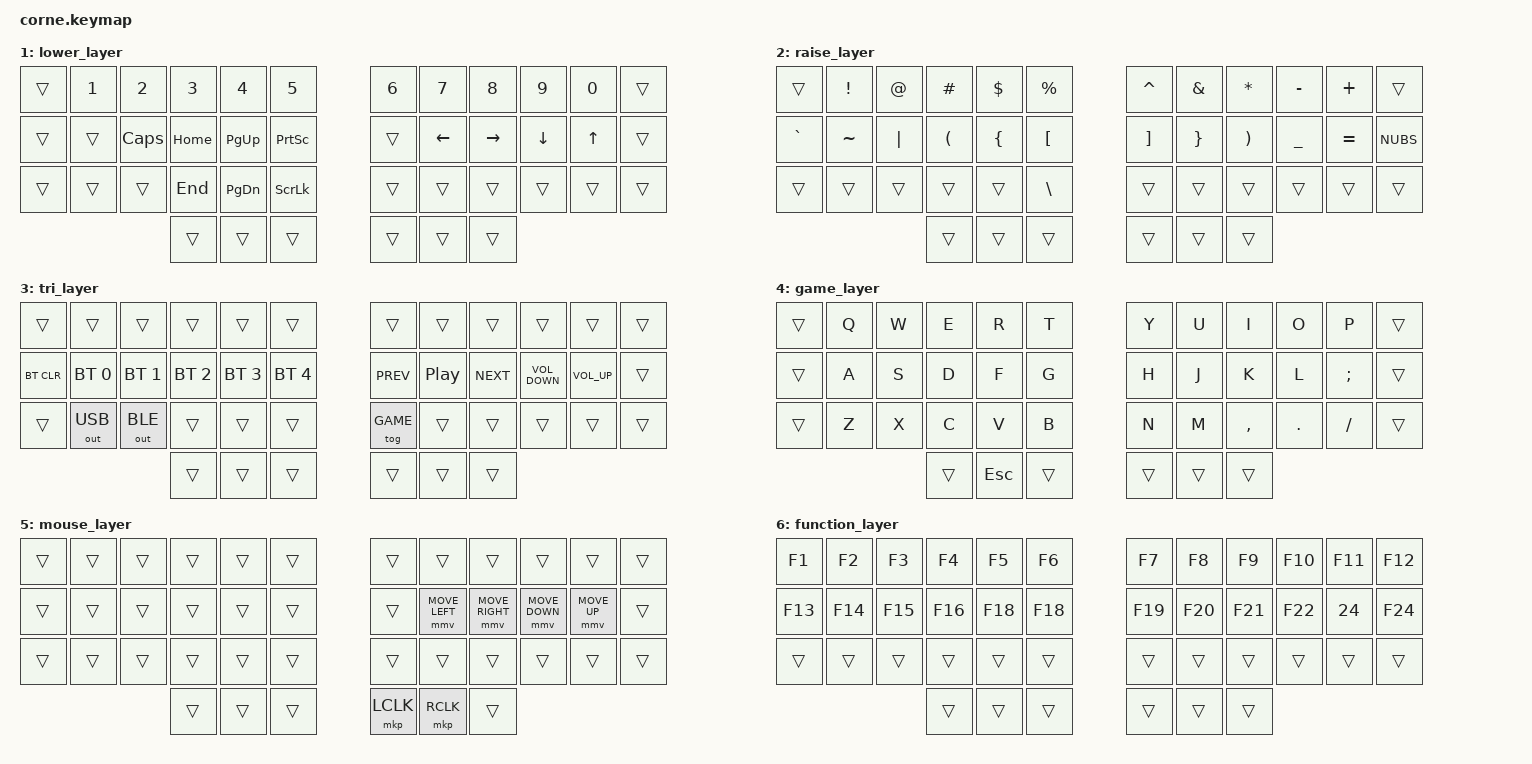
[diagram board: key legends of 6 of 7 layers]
#include <behaviors.dtsi>
#include <dt-bindings/zmk/keys.h>
#include <dt-bindings/zmk/outputs.h>
#include <dt-bindings/zmk/bt.h>
#include <dt-bindings/zmk/mouse.h>

// Home row mods macro
#define HRML(k2,k3,k4,k5) &ht LSHFT k2 &ht LALT  k3  &ht LCTRL k4  &ht LGUI  k5
#define HRMR(k1,k2,k3,k4) &ht LALT  k1 &ht RCTRL k2  &ht RGUI  k3  &ht RSHFT k4

#define ZMK_MOUSE_DEFAULT_MOVE_VAL 1500  // 600
#define ZMK_MOUSE_DEFAULT_SCRL_VAL 1    // 10

#define BASE 0
#define LOWER 1
#define RAISE 2
#define TRI 3
#define GAME 4
#define MOUSE 5
#define FUNCTION 6  

&mmv {
    acceleration-exponent = <1>;      // 1
    time-to-max-speed-ms = <500>;     // 300
    delay-ms = <0>;                   // 0
};

&msc {
    acceleration-exponent = <1>;      // 0
    time-to-max-speed-ms = <40>;      // 300
    delay-ms = <0>;                   // 0
};

&sk { 
    quick-release; 
};

&sl { 
quick-release;
};

/ {
        conditional_layers {
            compatible = "zmk,conditional-layers";
            tri_layer {
                if-layers = <LOWER RAISE>;
                then-layer = <TRI>;
            };
        };  

        behaviors {    
                ht: hold_tap {
                    label = "hold_tap";
                    compatible = "zmk,behavior-hold-tap";
                    #binding-cells = <2>;
                    flavor = "tap-preferred";
                    tapping-term-ms = <220>;
                    quick-tap-ms = <150>;
                    global-quick-tap;
                    bindings = <&kp>, <&kp>;
                };

                backspacenter: mod_del {
                    compatible = "zmk,behavior-mod-morph";
                    #binding-cells = <0>;
                    bindings = <&kp BSPC>, <&kp RET>;
                    mods = <(MOD_LCTL|MOD_RCTL)>;
                    keep-mods = <(MOD_RCTL)>;
                };

                spacedelete: grave_escape {
                    compatible = "zmk,behavior-mod-morph";
                    #binding-cells = <0>;
                    bindings = <&kp SPACE>, <&kp DEL>;
                    mods = <(MOD_LCTL|MOD_RCTL)>;
                    keep-mods = <(MOD_RCTL)>;
                };
        };

       combos {
            compatible = "zmk,combos";
                combo_exit_game_layer {
                    timeout-ms = <50>;
                    layers = <GAME>; // only on game layer
                    key-positions = <0 11>; // top left and top right keys
                    bindings = <&tog GAME>; // toggle game layer off
                };
                
                shift_combo {
                    timeout-ms = <50>;
                    slow-release;
                    key-positions = <38 39>;
                    bindings = <&sk LSHFT>;
                };

                function_combo {
                    timeout-ms = <50>;
                    slow-release;
                    key-positions = <37 39>;
                    bindings = <&sl 6>;
                };        
        };

        keymap {
                compatible = "zmk,keymap"; // rstlne layout 
                default_layer {
                         bindings = <
                // ╭──────────┬──────────┬──────────┬──────────┬──────────┬──────────╮       ╭──────────┬──────────┬──────────┬──────────┬──────────┬──────────╮
                // |  TAB     |  Q       |  W       |  D       |  F       |  /       |       |  J       |  U       |  K       |  Y       |  :       |  TAB    |
                     &kp TAB    &kp Q      &kp W      &kp D      &kp F      &kp FSLH           &kp J      &kp U      &kp K      &kp Y      &kp SEMI   &kp TAB
                // ├──────────┼──────────┼──────────┼──────────┼──────────┼──────────┤       ├──────────┼──────────┼──────────┼──────────┼──────────┼──────────┤
                // |  ESC     |  A       |  S       |  E       |  T       |  L       |       |  H       |  N       |  R       |  I       |  O       |  ESC     |
                     &kp ESC  HRML(A,      S,         E,         T)         &kp L              &kp H    HRMR(N,      R,         I,         O)         &kp ESC
                // ├──────────┼──────────┼──────────┼──────────┼──────────┼──────────┤       ├──────────┼──────────┼──────────┼──────────┼──────────┼──────────┤
                // |          |  G       |  X       |  C       |  V       |  Z       |       |  B       |  M       |  p       |  ,       |  .       |  "       |
                     &trans     &kp G      &kp X      &kp C      &kp V      &kp Z              &kp B      &kp M      &kp P      &kp COMMA  &kp DOT    &kp SQT
                // ╰──────────┴──────────┴──────────┼──────────┼──────────┼──────────┤       ├──────────┴──────────┴──────────┼──────────┼──────────┼──────────╯
                //                                  |  Mouse   |  LWR     |  SPC     |       |  ENT     |  RSE     |          |
                                                      &mo 5     &mo 1    &spacedelete       &backspacenter &mo 2     &trans
                //                                  ╰──────────┴──────────┴──────────╯       ╰──────────┴──────────┴──────────╯
                        >;
                };

        lower_layer {
                        bindings = <
                // ╭──────────┬──────────┬──────────┬──────────┬──────────┬──────────╮       ╭──────────┬──────────┬──────────┬──────────┬──────────┬──────────╮
                // |          |  1       |  2       |  3       |  4       |  5       |       |  6       |  7       |  8       |  9       |  0       |          |
                      &trans    &kp N1     &kp N2     &kp N3     &kp N4     &kp N5             &kp N6     &kp N7     &kp N8     &kp N9     &kp N0     &trans
                // ├──────────┼──────────┼──────────┼──────────┼──────────┼──────────┤       ├──────────┼──────────┼──────────┼──────────┼──────────┼──────────┤
                // |          |          |  CAPS    |  HOME    |  PGUP    |  PRSQ    |       |          |  left    |  right   |  DWN     |  UP      |          |
                      &trans    &trans     &kp CLCK   &kp HOME   &kp PG_UP  &kp PSCRN          &trans     &kp LEFT   &kp RIGHT  &kp DOWN   &kp UP     &trans
                // ├──────────┼──────────┼──────────┼──────────┼──────────┼──────────┤       ├──────────┼──────────┼──────────┼──────────┼──────────┼──────────┤
                // |          |          |          |  END     |  PGDN    |  SLCK    |       |          |          |          |          |          |          |
                      &trans    &trans     &trans     &kp END    &kp PG_DN  &kp SLCK           &trans     &trans     &trans     &trans     &trans     &trans
                // ╰──────────┴──────────┴──────────┼──────────┼──────────┼──────────┤       ├──────────┴──────────┴──────────┼──────────┼──────────┼──────────╯
                //                                  |          |          |          |       |          |          |          |
                                                      &trans     &trans     &trans             &trans     &trans     &trans
                //                                  ╰──────────┴──────────┴──────────╯       ╰──────────┴──────────┴──────────╯
                        >;
                };

        raise_layer {
                        bindings = <
                // ╭──────────┬──────────┬──────────┬──────────┬──────────┬──────────╮       ╭──────────┬──────────┬──────────┬──────────┬──────────┬──────────╮
                // |          |  !       |  @       |  #       |  $       |  %       |       |  ^       |  &       |  *       |  -       |  +       |          |
                      &trans    &kp EXCL   &kp AT     &kp HASH   &kp DLLR   &kp PRCNT          &kp CARET  &kp AMPS   &kp STAR   &kp MINUS  &kp PLUS   &trans
                // ├──────────┼──────────┼──────────┼──────────┼──────────┼──────────┤       ├──────────┼──────────┼──────────┼──────────┼──────────┼──────────┤
                // |          |          |  "|"     |  (       | {        |  [       |       |  ]       |  }       |  )       |  _       |  =       |          |
                      &kp GRAVE &kp TILDE  &kp PIPE   &kp LPAR  &kp LBRC   &kp LBKT            &kp RBKT   &kp RBRC   &kp RPAR   &kp UNDER  &kp EQUAL  &kp NUBS
                // ├──────────┼──────────┼──────────┼──────────┼──────────┼──────────┤       ├──────────┼──────────┼──────────┼──────────┼──────────┼──────────┤
                // |          |          |          |          |          |          |       |          |          |          |          |          |          |
                      &trans    &trans     &trans     &trans     &trans     &kp BSLH           &trans     &trans     &trans     &trans     &trans     &trans
                // ╰──────────┴──────────┴──────────┼──────────┼──────────┼──────────┤       ├──────────┴──────────┴──────────┼──────────┼──────────┼──────────╯
                //                                  |          |          |          |       |          |          |          |
                                                      &trans     &trans     &trans             &trans     &trans     &trans
                //                                  ╰──────────┴──────────┴──────────╯       ╰──────────┴──────────┴──────────╯
                        >;
                };
                
        tri_layer {
                        bindings = < 
                // ╭──────────┬──────────┬──────────┬──────────┬──────────┬──────────╮       ╭──────────┬──────────┬──────────┬──────────┬──────────┬──────────╮
                // |          |          |          |          |          |          |       |          |          |          |          |          |          |
                     &trans     &trans     &trans     &trans     &trans     &trans             &trans     &trans     &trans     &trans     &trans     &trans
                // ├──────────┼──────────┼──────────┼──────────┼──────────┼──────────┤       ├──────────┼──────────┼──────────┼──────────┼──────────┼──────────┤
                // |  BTCLR   |  BT1     |  BT2     |  BT3     | BT4      |  BT5     |       |  PREV    |  PLAY    |  NEXT    |  VO-     |  VO+     |          |
                   &bt BT_CLR &bt BT_SEL 0 &bt BT_SEL 1 &bt BT_SEL 2 &bt BT_SEL 3 &bt BT_SEL 4 &kp C_PREV &kp C_PP &kp C_NEXT &kp C_VOLUME_DOWN &kp C_VOL_UP &trans
                // ├──────────┼──────────┼──────────┼──────────┼──────────┼──────────┤       ├──────────┼──────────┼──────────┼──────────┼──────────┼──────────┤
                // |          |  USB     | BLUETOOH |          |          |          |       |  GAME    |          |          |          |          |          |
                     &trans   &out OUT_USB &out OUT_BLE &trans   &trans     &trans             &tog GAME  &trans     &trans     &trans     &trans     &trans
                // ╰──────────┴──────────┴──────────┼──────────┼──────────┼──────────┤       ├──────────┴──────────┴──────────┼──────────┼──────────┼──────────╯
                //                                  |          |          |          |       |          |          |          |
                                                      &trans     &trans     &trans             &trans     &trans     &trans
                //                                  ╰──────────┴──────────┴──────────╯       ╰──────────┴──────────┴──────────╯
                        >;
                };

        game_layer {
                        bindings = <
                // qwerty layer for gaming; exit by TAB + sql
                // ╭──────────┬──────────┬──────────┬──────────┬──────────┬──────────╮       ╭──────────┬──────────┬──────────┬──────────┬──────────┬──────────╮
                // |          |  Q       |  W       |  D       |  F       |  K       |       |  J       |  U       |  R       |  L       |  ;       |          |
                     &trans     &kp Q      &kp W      &kp E      &kp R      &kp T              &kp Y      &kp U      &kp I      &kp O      &kp P      &trans
                // ├──────────┼──────────┼──────────┼──────────┼──────────┼──────────┤       ├──────────┼──────────┼──────────┼──────────┼──────────┼──────────┤
                // |  CTRL    |  A       |  S       |  E       |  T       |  G       |       |  Y       |  N       |  I       |  O       |  H       |          |
                     &trans     &kp A      &kp S      &kp D      &kp F      &kp G              &kp H     &kp J       &kp K      &kp L      &kp SEMI   &trans
                // ├──────────┼──────────┼──────────┼──────────┼──────────┼──────────┤       ├──────────┼──────────┼──────────┼──────────┼──────────┼──────────┤
                // |  SHFT    |  Z       |  X       |  C       |  V       |  B       |       |  P       |  M       |  ,       |  .       |  /       |          |
                     &trans     &kp Z      &kp X      &kp C      &kp V      &kp B              &kp N      &kp M      &kp COMMA  &kp DOT    &kp FSLH   &trans
                // ╰──────────┴──────────┴──────────┼──────────┼──────────┼──────────┤       ├──────────┴──────────┴──────────┼──────────┼──────────┼──────────╯
                //                                  |  GUI     |  ESC     |  SPC     |       |  ENT     |  RSE     |  ALT     |
                                                      &trans     &kp ESC    &trans             &trans     &trans     &trans
                //                                  ╰──────────┴──────────┴──────────╯       ╰──────────┴──────────┴──────────╯
                        >;
                }; 

        mouse_layer {
                        bindings = <
                // ╭──────────┬──────────┬──────────┬──────────┬──────────┬──────────╮       ╭──────────┬──────────┬──────────┬──────────┬──────────┬──────────╮
                // |          |          |          |          |          |          |       |          |          |          |          |          |          |
                      &trans     &trans     &trans     &trans     &trans     &trans             &trans     &trans     &trans     &trans     &trans     &trans
                // ├──────────┼──────────┼──────────┼──────────┼──────────┼──────────┤       ├──────────┼──────────┼──────────┼──────────┼──────────┼──────────┤
                // |          |          |          |          |          |          |       |          |          |          |          |          |          |
                      &trans     &trans     &trans     &trans     &trans     &trans             &trans  &mmv MOVE_LEFT &mmv MOVE_RIGHT &mmv MOVE_DOWN &mmv MOVE_UP &trans
                // ├──────────┼──────────┼──────────┼──────────┼──────────┼──────────┤       ├──────────┼──────────┼──────────┼──────────┼──────────┼──────────┤
                // |          |          |          |          |          |          |       |          |          |          |          |          |          |
                      &trans     &trans     &trans     &trans     &trans     &trans             &trans     &trans     &trans     &trans     &trans     &trans
                // ╰──────────┴──────────┴──────────┼──────────┼──────────┼──────────┤       ├──────────┴──────────┴──────────┼──────────┼──────────┼──────────╯
                //                                  |          |          |          |       |          |          |          |
                                                       &trans     &trans     &trans            &mkp LCLK  &mkp RCLK   &trans
                //                                  ╰──────────┴──────────┴──────────╯       ╰──────────┴──────────┴──────────╯
                        >;
                };
               
        function_layer {
                        bindings = <
                // ╭──────────┬──────────┬──────────┬──────────┬──────────┬──────────╮       ╭──────────┬──────────┬──────────┬──────────┬──────────┬──────────╮
                // |   F1     |   F2     |   F3     |   F4     |   F5     |   F6     |       |   F7     |   F8     |   F9     |   F10    |   F11    |   F12    |
                      &kp F1     &kp F2     &kp F3     &kp F4     &kp F5     &kp F6             &kp F7     &kp F8     &kp F9     &kp F10    &kp F11    &kp F12
                // ├──────────┼──────────┼──────────┼──────────┼──────────┼──────────┤       ├──────────┼──────────┼──────────┼──────────┼──────────┼──────────┤
                // |   F13    |   F14    |   F15    |   F16    |   F17    |   F18    |       |   F19    |   F20    |   F21    |   F22    |   F23    |   F24    |
                      &kp F13    &kp F14   &kp F15     &kp F16    &kp F18    &kp F18            &kp F19    &kp F20    &kp F21    &kp F22    &kp 24    &kp F24
                // ├──────────┼──────────┼──────────┼──────────┼──────────┼──────────┤       ├──────────┼──────────┼──────────┼──────────┼──────────┼──────────┤
                // |          |          |          |          |          |          |       |          |          |          |          |          |          |
                      &trans     &trans     &trans     &trans     &trans     &trans             &trans     &trans     &trans     &trans     &trans     &trans
                // ╰──────────┴──────────┴──────────┼──────────┼──────────┼──────────┤       ├──────────┴──────────┴──────────┼──────────┼──────────┼──────────╯
                //                                  |          |          |          |       |          |          |          |
                                                       &trans     &trans     &trans             &trans     &trans     &trans
                //                                  ╰──────────┴──────────┴──────────╯       ╰──────────┴──────────┴──────────╯
                        >;
                };
        };
};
